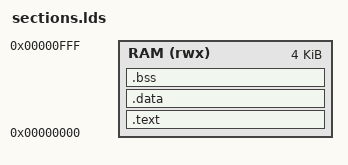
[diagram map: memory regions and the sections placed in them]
/* AUTO-GENERATED BY gen_config.py - DO NOT EDIT MANUALLY */
/* Generated:     2026-03-30 22:51:21 */
/* RAM base:      0x00000000  size: 4096 B */
/* Reset vector:  0x00000000 */
/* Stack:         25% of RAM = 1024 B */

OUTPUT_ARCH(riscv)
ENTRY(_start)

MEMORY {
  RAM (rwx) : ORIGIN = 0x00000000, LENGTH = 4096
}

SECTIONS {
  .text : {
    KEEP(*(.text.start))
    *(.text*)
    *(.rodata*)
  } > RAM

  .data : {
    *(.data*)
  } > RAM

  .bss : {
    __bss_start = .;
    *(.bss*) *(COMMON)
    . = ALIGN(4);
    __bss_end = .;
  } > RAM

  /* Stack grows downward from top of RAM */
  /* Stack size = 25% of 4096 B = 1024 B */
  _stack_top  = ORIGIN(RAM) + LENGTH(RAM);
  _stack_size = LENGTH(RAM) * 25 / 100;
  _stack_base = _stack_top - _stack_size;
}
